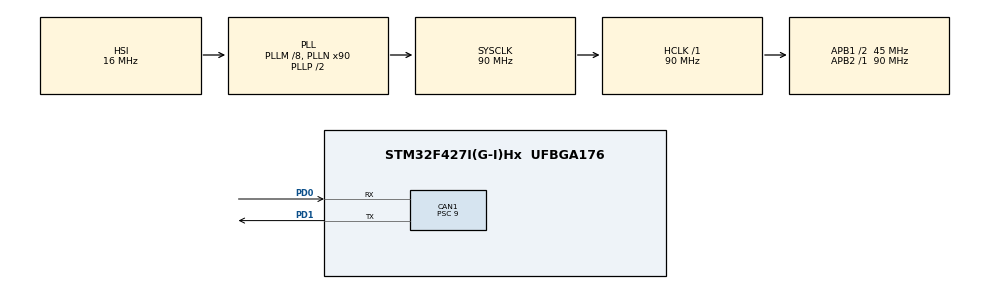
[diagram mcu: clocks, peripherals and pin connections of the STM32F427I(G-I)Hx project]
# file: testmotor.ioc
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CAN1.BS1=CAN_BS1_2TQ
CAN1.BS2=CAN_BS2_2TQ
CAN1.CalculateBaudRate=1000000
CAN1.CalculateTimeBit=1000
CAN1.CalculateTimeQuantum=200.0
CAN1.Prescaler=9
Mcu.Family=STM32F4
Mcu.Name=STM32F427I(G-I)Hx
Mcu.Package=UFBGA176
NVIC.CAN1_RX0_IRQn=true\:0\:0\:false\:false\:true\:true\:true\:true
NVIC.PriorityGroup=NVIC_PRIORITYGROUP_4
PA13.Mode=Serial_Wire
PA13.Signal=SYS_JTMS-SWDIO
PA14.Mode=Serial_Wire
PA14.Signal=SYS_JTCK-SWCLK
PD0.Mode=CAN_Activate
PD0.Signal=CAN1_RX
PD1.Mode=CAN_Activate
PD1.Signal=CAN1_TX
PH0/OSC_IN.Mode=HSE-External-Oscillator
PH0/OSC_IN.Signal=RCC_OSC_IN
PH1/OSC_OUT.Mode=HSE-External-Oscillator
PH1/OSC_OUT.Signal=RCC_OSC_OUT
ProjectManager.HeapSize=0x200
ProjectManager.StackSize=0x400
ProjectManager.TargetToolchain=MDK-ARM V5.32
RCC.48MHZClocksFreq_Value=45000000
RCC.AHBFreq_Value=90000000
RCC.APB1CLKDivider=RCC_HCLK_DIV2
RCC.APB1Freq_Value=45000000
RCC.APB1TimFreq_Value=90000000
RCC.APB2Freq_Value=90000000
RCC.APB2TimFreq_Value=90000000
RCC.CortexFreq_Value=90000000
RCC.HCLKFreq_Value=90000000
RCC.HSE_VALUE=12000000
RCC.HSI_VALUE=16000000
RCC.LSE_VALUE=32768
RCC.PLLM=8
RCC.PLLN=90
RCC.SYSCLKFreq_VALUE=90000000
RCC.SYSCLKSource=RCC_SYSCLKSOURCE_PLLCLK
RCC.VCOOutputFreq_Value=180000000
board=custom

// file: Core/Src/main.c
/* USER CODE BEGIN Header */
/**
  ******************************************************************************
  * @file           : main.c
  * @brief          : Main program body
  ******************************************************************************
  * @attention
  *
  * Copyright (c) 2023 STMicroelectronics.
  * All rights reserved.
  *
  * This software is licensed under terms that can be found in the LICENSE file
  * in the root directory of this software component.
  * If no LICENSE file comes with this software, it is provided AS-IS.
  *
  ******************************************************************************
  */
/* USER CODE END Header */
#include "main.h"
#include "can.h"
#include "gpio.h"

/* USER CODE BEGIN PD */
#define LimitMax(input, max)   \
    {                          \
        if (input > max)       \
        {                      \
            input = max;       \
        }                      \
        else if (input < -max) \
        {                      \
            input = -max;      \
        }                      \
    }
/* USER CODE END PD */

void SystemClock_Config(void);
/* USER CODE BEGIN PFP */
void pid_init(pid_struct_t *pid,   float PID[3], float max_out, float max_iout) ;
float PIDcal(pid_struct_t* pid,float get,float set);

/* USER CODE END PFP */

/* USER CODE BEGIN 0 */
void startmotor(int16_t setspeed);
pid_struct_t motor_pid;
extern motor_info_t  motor_info_chassis;
float set_motor_pid [3]={5,0.5,10};
const float motor_speed_target=1;
/* USER CODE END 0 */

int main(void)
{

  /* MCU Configuration--------------------------------------------------------*/

  /* Reset of all peripherals, Initializes the Flash interface and the Systick. */
  HAL_Init();

  /* Configure the system clock */
  SystemClock_Config();

  /* Initialize all configured peripherals */
  MX_GPIO_Init();
  MX_CAN1_Init();
  /* USER CODE BEGIN 2 */
  CAN1_Init();
  pid_init(&motor_pid,set_motor_pid,1000,1000);

  /* USER CODE END 2 */

  /* Infinite loop */
  while (1)
  {

    /* USER CODE BEGIN 3 */
     startmotor(motor_info_chassis.set_current);
  }
  /* USER CODE END 3 */
}

void SystemClock_Config(void)
{
  RCC_OscInitTypeDef RCC_OscInitStruct = {0};
  RCC_ClkInitTypeDef RCC_ClkInitStruct = {0};

  /** Configure the main internal regulator output voltage
  */
  __HAL_RCC_PWR_CLK_ENABLE();
  __HAL_PWR_VOLTAGESCALING_CONFIG(PWR_REGULATOR_VOLTAGE_SCALE3);

  /** Initializes the RCC Oscillators according to the specified parameters
  * in the RCC_OscInitTypeDef structure.
  */
  RCC_OscInitStruct.OscillatorType = RCC_OSCILLATORTYPE_HSI;
  RCC_OscInitStruct.HSIState = RCC_HSI_ON;
  RCC_OscInitStruct.HSICalibrationValue = RCC_HSICALIBRATION_DEFAULT;
  RCC_OscInitStruct.PLL.PLLState = RCC_PLL_ON;
  RCC_OscInitStruct.PLL.PLLSource = RCC_PLLSOURCE_HSI;
  RCC_OscInitStruct.PLL.PLLM = 8;
  RCC_OscInitStruct.PLL.PLLN = 90;
  RCC_OscInitStruct.PLL.PLLP = RCC_PLLP_DIV2;
  RCC_OscInitStruct.PLL.PLLQ = 4;
  if (HAL_RCC_OscConfig(&RCC_OscInitStruct) != HAL_OK)
  {
    Error_Handler();
  }

  /** Activate the Over-Drive mode
  */
  if (HAL_PWREx_EnableOverDrive() != HAL_OK)
  {
    Error_Handler();
  }

  /** Initializes the CPU, AHB and APB buses clocks
  */
  RCC_ClkInitStruct.ClockType = RCC_CLOCKTYPE_HCLK|RCC_CLOCKTYPE_SYSCLK
                              |RCC_CLOCKTYPE_PCLK1|RCC_CLOCKTYPE_PCLK2;
  RCC_ClkInitStruct.SYSCLKSource = RCC_SYSCLKSOURCE_PLLCLK;
  RCC_ClkInitStruct.AHBCLKDivider = RCC_SYSCLK_DIV1;
  RCC_ClkInitStruct.APB1CLKDivider = RCC_HCLK_DIV2;
  RCC_ClkInitStruct.APB2CLKDivider = RCC_HCLK_DIV1;

  if (HAL_RCC_ClockConfig(&RCC_ClkInitStruct, FLASH_LATENCY_2) != HAL_OK)
  {
    Error_Handler();
  }
}

/* USER CODE BEGIN 4 */
void startmotor(int16_t setspeed)
{
    motor_info_chassis.set_current = PIDcal(&motor_pid, motor_info_chassis.rotor_speed,motor_speed_target);
    set_motor_speed(motor_info_chassis.set_current);
}

void pid_init(pid_struct_t *pid,   float PID[3], float max_out, float max_iout)   //pid结构体初始化，后两个参数分别设置输出最大值，积分最大值
{
    if (pid == NULL || PID == NULL)
    {
        return;
    }

    pid->Kp = PID[0];
    pid->Ki = PID[1];
    pid->Kd = PID[2];
    pid->max_out = max_out;
    pid->max_iout = max_iout;
    pid->Dbuf[0] = pid->Dbuf[1] = pid->Dbuf[2] = 0.0f;
    pid->error[0] = pid->error[1] = pid->error[2] = pid->Pout = pid->Iout = pid->Dout = pid->out = 0.0f;
}

float PIDcal(pid_struct_t* pid,float get,float set)
{
  pid->error[1] = pid->error[0];
  pid->set = set;
  pid->get = get;
  pid->error[0] = set - get;

  pid->Pout = pid->Kp * pid->error[0];
  pid->Iout += pid->Ki * pid->error[0];

  pid->Dbuf[1] = pid->Dbuf[0];
  pid->Dbuf[0] = (pid->error[0] - pid->error[1]);
  pid->Dout = pid->Kd * pid->Dbuf[0];
  LimitMax(pid->Iout, pid->max_iout);
  pid->out = pid->Pout + pid->Iout + pid->Dout;
  LimitMax(pid->out, pid->max_out);
  return pid->out;
}

/* USER CODE END 4 */

void Error_Handler(void)
{
  __disable_irq();
  while (1)
  {
  }
}
